# iospear300 register map
Registers are 32-bit, access not given, no defined reset value unless marked. A register's access mark holds for its fields unless they carry their own. Addresses are absolute; registers are grouped by the start of their names; [hi:lo] are bit positions; {n}, {i} and the like mark numbered series.

## ADC
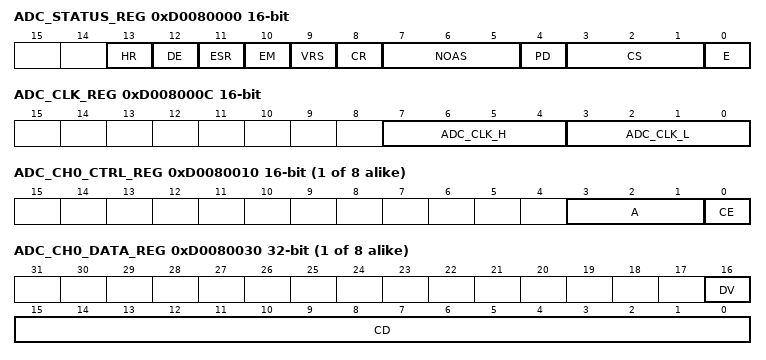
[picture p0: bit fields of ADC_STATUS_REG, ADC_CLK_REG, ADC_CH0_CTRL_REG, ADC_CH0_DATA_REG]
0xD0080000 ADC_STATUS_REG 16-bit
  [13] HR, [12] DE, [11] ESR, [10] EM, [9] VRS, [8] CR, [7:5] NOAS, [4] PD, [3:1] CS, [0] E
0xD0080004 ADC_AVERAGE_REG 16-bit
  [9:0] CD
0xD0080008 ADC_SCAN_RATE_REG
0xD008000C ADC_CLK_REG 16-bit
  [7:4] ADC_CLK_H, [3:0] ADC_CLK_L
{0xD0080010+4i} ADC_CH{i}_CTRL_REG 16-bit (i=0..7)
  [3:1] A, [0] CE
{0xD0080030+4i} ADC_CH{i}_DATA_REG (i=0..7)
  [16] DV, [15:0] CD

## GenMemCtrl
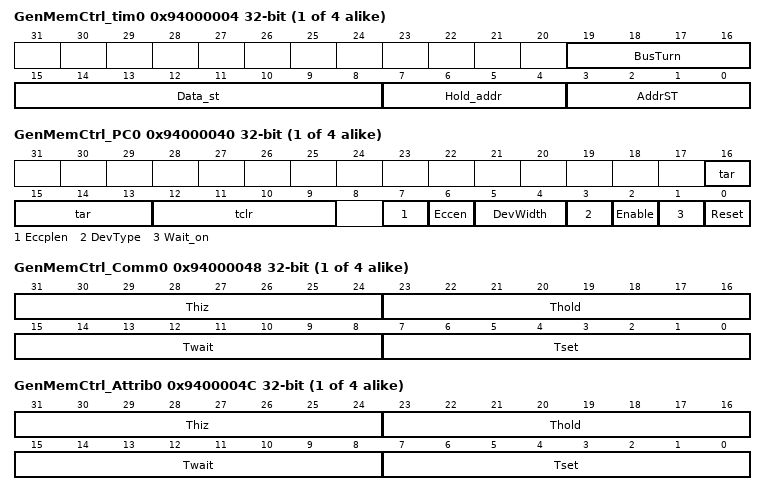
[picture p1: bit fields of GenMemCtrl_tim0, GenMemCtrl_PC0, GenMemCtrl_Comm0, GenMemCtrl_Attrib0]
{0x94000004+8i} GenMemCtrl_tim{i} (i=0..3)
  [19:16] BusTurn, [15:8] Data_st, [7:4] Hold_addr, [3:0] AddrST
{0x94000040+0x20*i} GenMemCtrl_PC{i} (i=0..3)
  [16:13] tar, [12:9] tclr, [7] Eccplen, [6] Eccen, [5:4] DevWidth, [3] DevType, [2] Enable, [1] Wait_on, [0] Reset
{0x94000048+0x20*i} GenMemCtrl_Comm{i} (i=0..3)
  [31:24] Thiz, [23:16] Thold, [15:8] Twait, [7:0] Tset
{0x9400004C+0x20*i} GenMemCtrl_Attrib{i} (i=0..3)
  [31:24] Thiz, [23:16] Thold, [15:8] Twait, [7:0] Tset
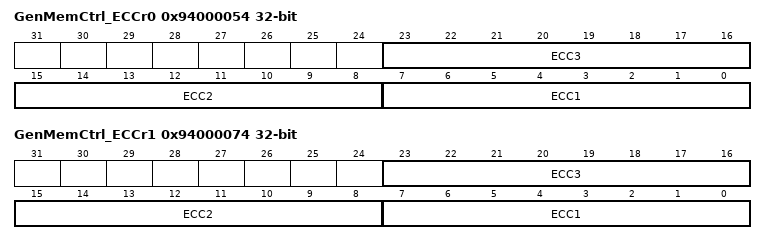
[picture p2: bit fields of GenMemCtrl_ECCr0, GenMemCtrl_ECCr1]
0x94000054 GenMemCtrl_ECCr0
  [23:16] ECC3, [15:8] ECC2, [7:0] ECC1
0x94000074 GenMemCtrl_ECCr1
  [23:16] ECC3, [15:8] ECC2, [7:0] ECC1
{0x94000FE0+4i} GenMemCtrl_PeriphID{i} (i=0..3)
{0x94000FF0+4i} GenMemCtrl_PCellID{i} (i=0..3)

## RS
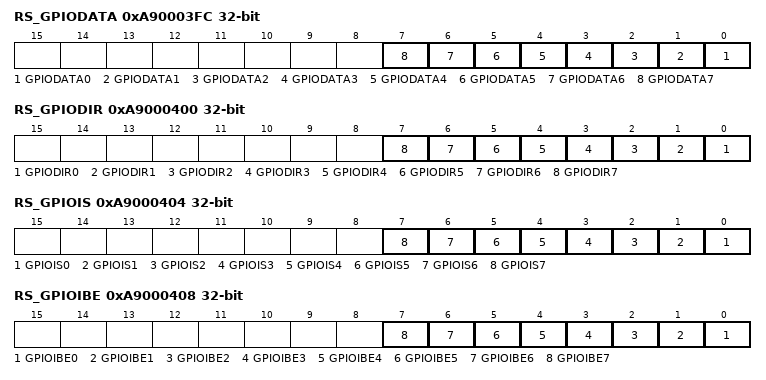
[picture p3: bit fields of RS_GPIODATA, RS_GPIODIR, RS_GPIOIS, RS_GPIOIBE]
0xA90003FC RS_GPIODATA
  [n] GPIODATA{n} (n=0..7)
0xA9000400 RS_GPIODIR
  [n] GPIODIR{n} (n=0..7)
0xA9000404 RS_GPIOIS
  [n] GPIOIS{n} (n=0..7)
0xA9000408 RS_GPIOIBE
  [n] GPIOIBE{n} (n=0..7)
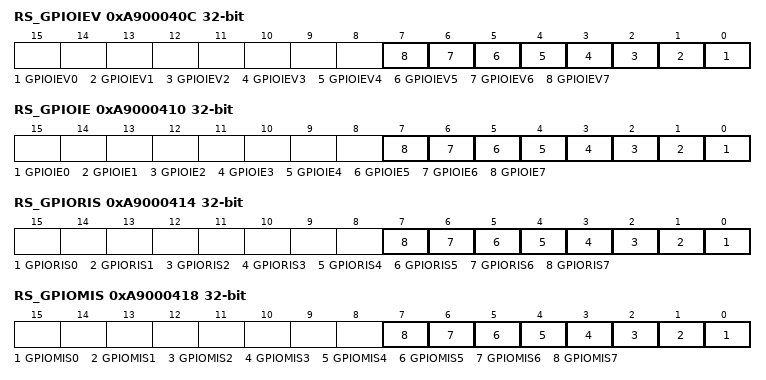
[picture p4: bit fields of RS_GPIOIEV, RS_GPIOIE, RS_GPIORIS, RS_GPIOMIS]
0xA900040C RS_GPIOIEV
  [n] GPIOIEV{n} (n=0..7)
0xA9000410 RS_GPIOIE
  [n] GPIOIE{n} (n=0..7)
0xA9000414 RS_GPIORIS
  [n] GPIORIS{n} (n=0..7)
0xA9000418 RS_GPIOMIS
  [n] GPIOMIS{n} (n=0..7)
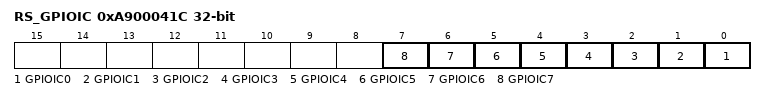
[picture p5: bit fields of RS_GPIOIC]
0xA900041C RS_GPIOIC
  [n] GPIOIC{n} (n=0..7)
{0xA9000FE0+4i} RS_GPIOPeriphID{i} 16-bit (i=0..3)
{0xA9000FF0+4i} RS_GPIOPCellID{i} 16-bit (i=0..3)

## TELECOM
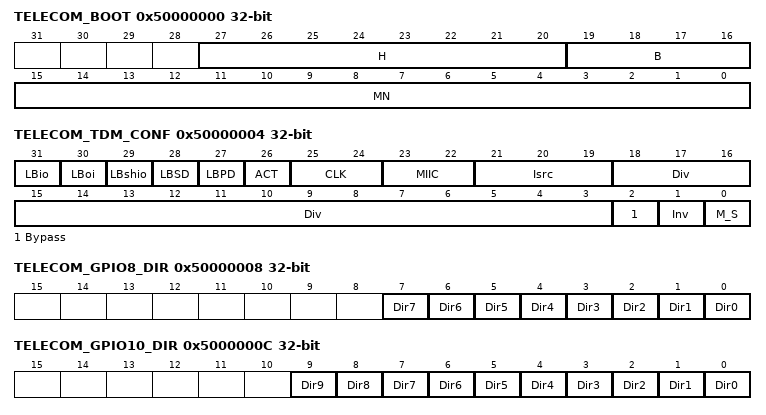
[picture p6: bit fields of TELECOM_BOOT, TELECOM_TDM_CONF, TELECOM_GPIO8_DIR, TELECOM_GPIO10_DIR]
0x50000000 TELECOM_BOOT
  [27:20] H, [19:16] B, [15:0] MN
0x50000004 TELECOM_TDM_CONF
  [31] LBio, [30] LBoi, [29] LBshio, [28] LBSD, [27] LBPD, [26] ACT, [25:24] CLK, [23:22] MIIC, [21:19] Isrc, [18:3] Div, [2] Bypass, [1] Inv, [0] M_S
0x50000008 TELECOM_GPIO8_DIR
  [n] Dir{n} (n=0..7)
0x5000000C TELECOM_GPIO10_DIR
  [n] Dir{n} (n=0..9)
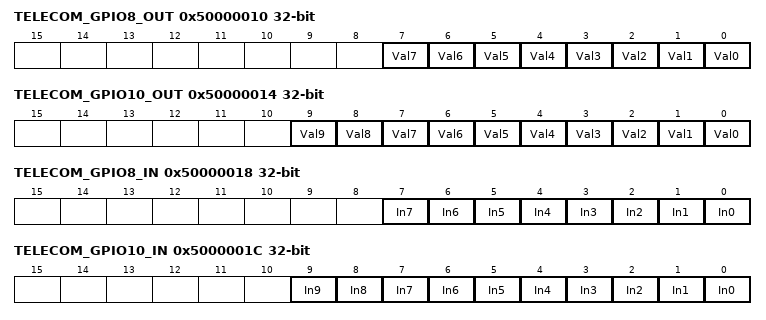
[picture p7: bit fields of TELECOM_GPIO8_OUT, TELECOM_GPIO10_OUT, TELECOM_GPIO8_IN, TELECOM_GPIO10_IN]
0x50000010 TELECOM_GPIO8_OUT
  [n] Val{n} (n=0..7)
0x50000014 TELECOM_GPIO10_OUT
  [n] Val{n} (n=0..9)
0x50000018 TELECOM_GPIO8_IN
  [n] In{n} (n=0..7)
0x5000001C TELECOM_GPIO10_IN
  [n] In{n} (n=0..9)
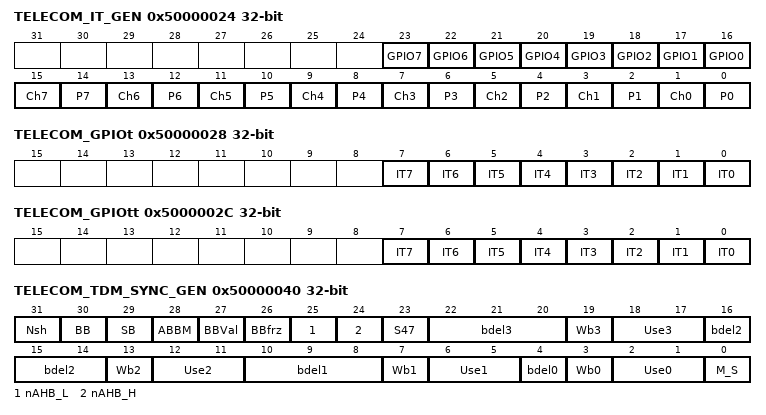
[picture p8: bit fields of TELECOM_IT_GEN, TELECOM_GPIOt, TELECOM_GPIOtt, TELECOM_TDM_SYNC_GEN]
0x50000024 TELECOM_IT_GEN
  [n+16] GPIO{n} (n=0..7), [2n+1] Ch{n} (n=0..7), [2n] P{n} (n=0..7)
0x50000028 TELECOM_GPIOt
  [n] IT{n} (n=0..7)
0x5000002C TELECOM_GPIOtt
  [n] IT{n} (n=0..7)
0x50000030 TELECOM_PERS_TIME
  [7:0] PT
0x50000034 TELECOM_PERS_DATA
  [7:0] PV
0x50000038 TELECOM_TDM_TSLOT_NBR
  [10:0] TSN
0x5000003C TELECOM_TDM_FRAME_NBR
  [14:0] FRN
0x50000040 TELECOM_TDM_SYNC_GEN
  [31] Nsh, [30] BB, [29] SB, [28] ABBM, [27] BBVal, [26] BBfrz, [25] nAHB_L, [24] nAHB_H, [23] S47, [22:20] bdel3, [19] Wb3, [18:17] Use3, [16:14] bdel2, [13] Wb2, [12:11] Use2, [10:8] bdel1, [7] Wb1, [6:5] Use1, [4] bdel0, [3] Wb0, [2:1] Use0, [0] M_S
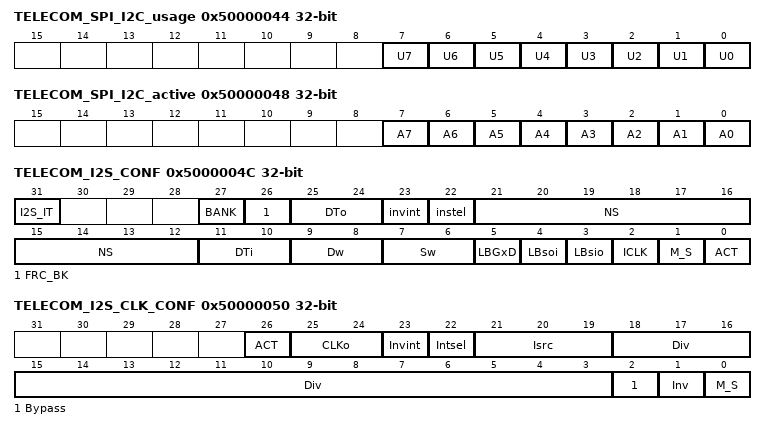
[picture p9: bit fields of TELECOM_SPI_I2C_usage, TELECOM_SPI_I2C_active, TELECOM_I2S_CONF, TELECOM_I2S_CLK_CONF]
0x50000044 TELECOM_SPI_I2C_usage
  [n] U{n} (n=0..7)
0x50000048 TELECOM_SPI_I2C_active
  [n] A{n} (n=0..7)
0x5000004C TELECOM_I2S_CONF
  [31] I2S_IT, [27] BANK, [26] FRC_BK, [25:24] DTo, [23] invint, [22] instel, [21:12] NS, [11:10] DTi, [9:8] Dw, [7:6] Sw, [5] LBGxD, [4] LBsoi, [3] LBsio, [2] ICLK, [1] M_S, [0] ACT
0x50000050 TELECOM_I2S_CLK_CONF
  [26] ACT, [25:24] CLKo, [23] Invint, [22] Intsel, [21:19] Isrc, [18:3] Div, [2] Bypass, [1] Inv, [0] M_S
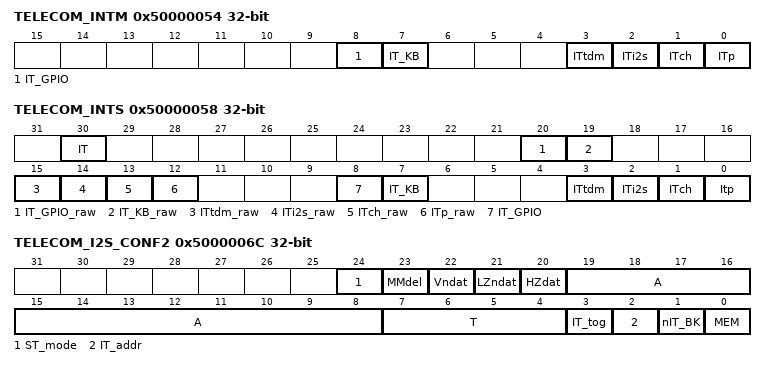
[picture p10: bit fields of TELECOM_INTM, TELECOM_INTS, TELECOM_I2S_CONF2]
0x50000054 TELECOM_INTM
  [8] IT_GPIO, [7] IT_KB, [3] ITtdm, [2] ITi2s, [1] ITch, [0] ITp
0x50000058 TELECOM_INTS
  [30] IT, [20] IT_GPIO_raw, [19] IT_KB_raw, [15] ITtdm_raw, [14] ITi2s_raw, [13] ITch_raw, [12] ITp_raw, [8] IT_GPIO, [7] IT_KB, [3] ITtdm, [2] ITi2s, [1] ITch, [0] Itp
0x5000006C TELECOM_I2S_CONF2
  [24] ST_mode, [23] MMdel, [22] Vndat, [21] LZndat, [20] HZdat, [19:8] A, [7:4] T, [3] IT_tog, [2] IT_addr, [1] nIT_BK, [0] MEM
